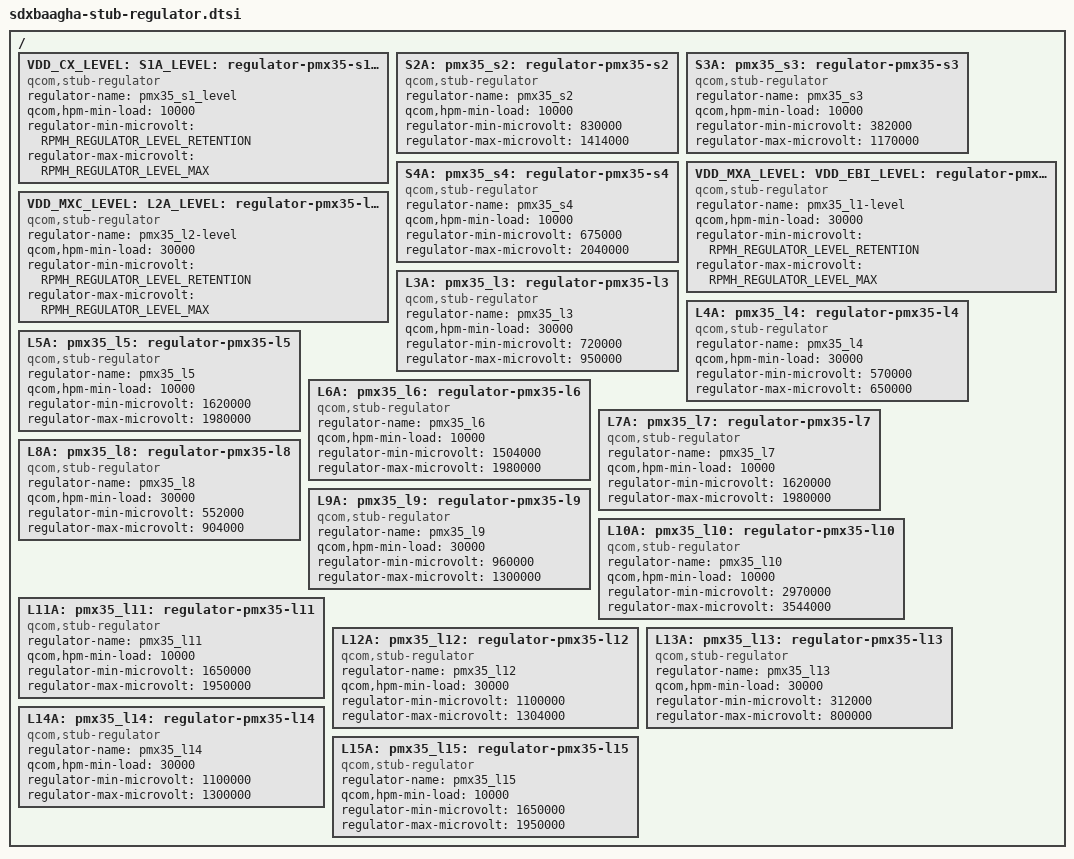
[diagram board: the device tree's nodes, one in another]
#include <dt-bindings/regulator/qcom,rpmh-regulator-levels.h>

/ {
	VDD_CX_LEVEL:
	S1A_LEVEL:
	pmx35_s1_level: regulator-pmx35-s1-level {
		compatible = "qcom,stub-regulator";
		regulator-name = "pmx35_s1_level";
		qcom,hpm-min-load = <10000>;
		regulator-min-microvolt =
			<RPMH_REGULATOR_LEVEL_RETENTION>;
		regulator-max-microvolt = <RPMH_REGULATOR_LEVEL_MAX>;

	};

	S2A:
	pmx35_s2: regulator-pmx35-s2 {
		compatible = "qcom,stub-regulator";
		regulator-name = "pmx35_s2";
		qcom,hpm-min-load = <10000>;
		regulator-min-microvolt = <830000>;
		regulator-max-microvolt = <1414000>;
	};

	S3A:
	pmx35_s3: regulator-pmx35-s3 {
		compatible = "qcom,stub-regulator";
		regulator-name = "pmx35_s3";
		qcom,hpm-min-load = <10000>;
		regulator-min-microvolt = <382000>;
		regulator-max-microvolt = <1170000>;
	};

	S4A:
	pmx35_s4: regulator-pmx35-s4 {
		compatible = "qcom,stub-regulator";
		regulator-name = "pmx35_s4";
		qcom,hpm-min-load = <10000>;
		regulator-min-microvolt = <675000>;
		regulator-max-microvolt = <2040000>;
	};

	VDD_MXA_LEVEL:
	VDD_EBI_LEVEL:
	L1A_LEVEL:
	pmx35_l1_level: regulator-pmx35-l1-level {
		compatible = "qcom,stub-regulator";
		regulator-name = "pmx35_l1-level";
		qcom,hpm-min-load = <30000>;
		regulator-min-microvolt =
			<RPMH_REGULATOR_LEVEL_RETENTION>;
		regulator-max-microvolt = <RPMH_REGULATOR_LEVEL_MAX>;
	};

	VDD_MXC_LEVEL:
	L2A_LEVEL:
	pmx35_l2_level: regulator-pmx35-l2-level {
		compatible = "qcom,stub-regulator";
		regulator-name = "pmx35_l2-level";
		qcom,hpm-min-load = <30000>;
		regulator-min-microvolt =
			<RPMH_REGULATOR_LEVEL_RETENTION>;
		regulator-max-microvolt = <RPMH_REGULATOR_LEVEL_MAX>;
	};

	L3A:
	pmx35_l3: regulator-pmx35-l3 {
		compatible = "qcom,stub-regulator";
		regulator-name = "pmx35_l3";
		qcom,hpm-min-load = <30000>;
		regulator-min-microvolt = <720000>;
		regulator-max-microvolt = <950000>;
	};

	L4A:
	pmx35_l4: regulator-pmx35-l4 {
		compatible = "qcom,stub-regulator";
		regulator-name = "pmx35_l4";
		qcom,hpm-min-load = <30000>;
		regulator-min-microvolt = <570000>;
		regulator-max-microvolt = <650000>;
	};

	L5A:
	pmx35_l5: regulator-pmx35-l5 {
		compatible = "qcom,stub-regulator";
		regulator-name = "pmx35_l5";
		qcom,hpm-min-load = <10000>;
		regulator-min-microvolt = <1620000>;
		regulator-max-microvolt = <1980000>;
	};

	L6A:
	pmx35_l6: regulator-pmx35-l6 {
		compatible = "qcom,stub-regulator";
		regulator-name = "pmx35_l6";
		qcom,hpm-min-load = <10000>;
		regulator-min-microvolt = <1504000>;
		regulator-max-microvolt = <1980000>;
	};

	L7A:
	pmx35_l7: regulator-pmx35-l7 {
		compatible = "qcom,stub-regulator";
		regulator-name = "pmx35_l7";
		qcom,hpm-min-load = <10000>;
		regulator-min-microvolt = <1620000>;
		regulator-max-microvolt = <1980000>;
	};

	L8A:
	pmx35_l8: regulator-pmx35-l8 {
		compatible = "qcom,stub-regulator";
		regulator-name = "pmx35_l8";
		qcom,hpm-min-load = <30000>;
		regulator-min-microvolt = <552000>;
		regulator-max-microvolt = <904000>;
	};

	L9A:
	pmx35_l9: regulator-pmx35-l9 {
		compatible = "qcom,stub-regulator";
		regulator-name = "pmx35_l9";
		qcom,hpm-min-load = <30000>;
		regulator-min-microvolt = <960000>;
		regulator-max-microvolt = <1300000>;
	};

	L10A:
	pmx35_l10: regulator-pmx35-l10 {
		compatible = "qcom,stub-regulator";
		regulator-name = "pmx35_l10";
		qcom,hpm-min-load = <10000>;
		regulator-min-microvolt = <2970000>;
		regulator-max-microvolt = <3544000>;
	};

	L11A:
	pmx35_l11: regulator-pmx35-l11 {
		compatible = "qcom,stub-regulator";
		regulator-name = "pmx35_l11";
		qcom,hpm-min-load = <10000>;
		regulator-min-microvolt = <1650000>;
		regulator-max-microvolt = <1950000>;
	};

	L12A:
	pmx35_l12: regulator-pmx35-l12 {
		compatible = "qcom,stub-regulator";
		regulator-name = "pmx35_l12";
		qcom,hpm-min-load = <30000>;
		regulator-min-microvolt = <1100000>;
		regulator-max-microvolt = <1304000>;
	};

	L13A:
	pmx35_l13: regulator-pmx35-l13 {
		compatible = "qcom,stub-regulator";
		regulator-name = "pmx35_l13";
		qcom,hpm-min-load = <30000>;
		regulator-min-microvolt = <312000>;
		regulator-max-microvolt = <800000>;
	};

	L14A:
	pmx35_l14: regulator-pmx35-l14 {
		compatible = "qcom,stub-regulator";
		regulator-name = "pmx35_l14";
		qcom,hpm-min-load = <30000>;
		regulator-min-microvolt = <1100000>;
		regulator-max-microvolt = <1300000>;
	};

	L15A:
	pmx35_l15: regulator-pmx35-l15 {
		compatible = "qcom,stub-regulator";
		regulator-name = "pmx35_l15";
		qcom,hpm-min-load = <10000>;
		regulator-min-microvolt = <1650000>;
		regulator-max-microvolt = <1950000>;
	};
};
